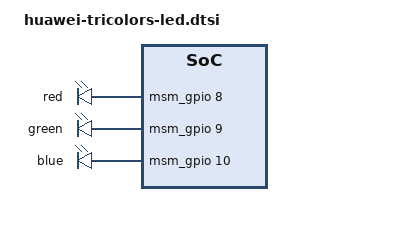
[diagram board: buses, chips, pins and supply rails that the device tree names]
/* Copyright (c) 2013, The Linux Foundation. All rights reserved.
 *
 * This program is free software; you can redistribute it and/or modify
 * it under the terms of the GNU General Public License version 2 and
 * only version 2 as published by the Free Software Foundation.
 *
 * This program is distributed in the hope that it will be useful,
 * but WITHOUT ANY WARRANTY; without even the implied warranty of
 * MERCHANTABILITY or FITNESS FOR A PARTICULAR PURPOSE.  See the
 * GNU General Public License for more details.
 */

/* three color led device node */
&soc {
	gpio-leds {
		compatible = "gpio-leds";
		status = "okay";
		pinctrl-names = "default";
		pinctrl-0 = <&gpio_led_off>;
		red {
			gpios = <&msm_gpio 8 0>;
			label = "red";
			linux,default-trigger = "none";
			default-state = "off";
		};

		green {
			gpios = <&msm_gpio 9 0>;
			label = "green";
			linux,default-trigger = "none";
			default-state = "off";
		};
		blue {
			gpios = <&msm_gpio 10 0>;
			label = "blue";
			linux,default-trigger = "none";
			default-state = "off";
		};
	};
};

